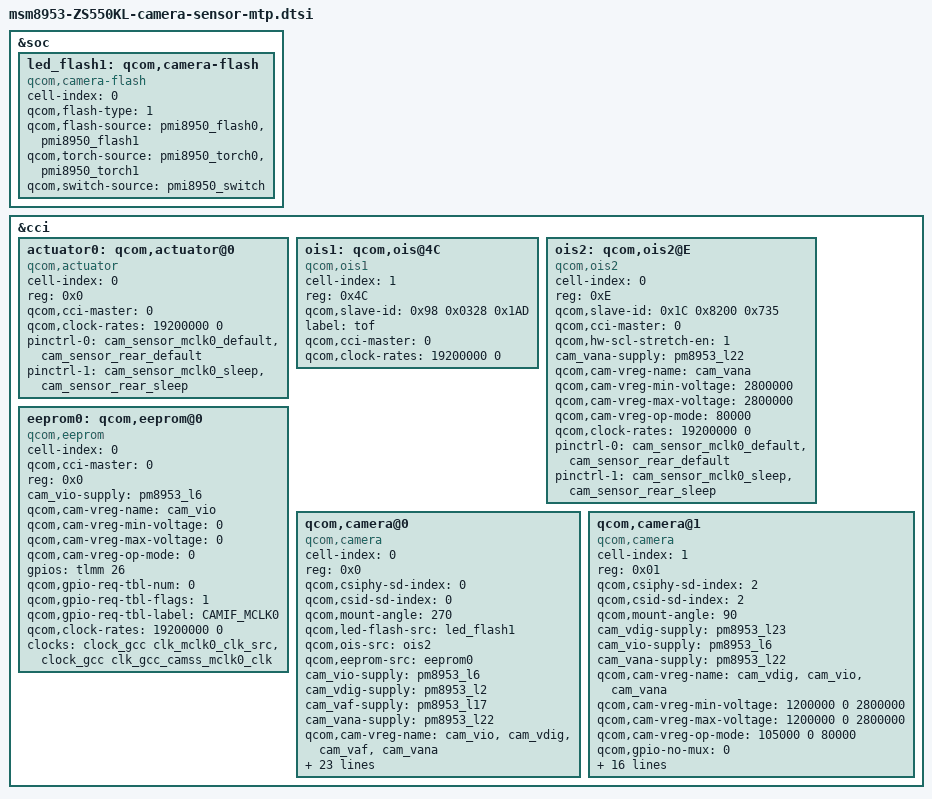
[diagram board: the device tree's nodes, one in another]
/*
 * Copyright (c) 2015-2016, The Linux Foundation. All rights reserved.
 *
 * This program is free software; you can redistribute it and/or modify
 * it under the terms of the GNU General Public License version 2 and
 * only version 2 as published by the Free Software Foundation.
 *
 * This program is distributed in the hope that it will be useful,
 * but WITHOUT ANY WARRANTY; without even the implied warranty of
 * MERCHANTABILITY or FITNESS FOR A PARTICULAR PURPOSE.  See the
 * GNU General Public License for more details.
 */

&soc {

	led_flash1: qcom,camera-flash {
		cell-index = <0>;
		compatible = "qcom,camera-flash";
		qcom,flash-type = <1>;
		qcom,flash-source = <&pmi8950_flash0 &pmi8950_flash1>;
		qcom,torch-source = <&pmi8950_torch0 &pmi8950_torch1>;
		qcom,switch-source = <&pmi8950_switch>;
	};
	
};

&cci {
/*
	led_flash0: qcom,camera-flash@37 {
		cell-index = <0>;
		reg = <0x37>;
		qcom,slave-id = <0x6E 0x00 0x0011>;
		compatible = "qcom,camera-flash";
		label = "sky81296";
		qcom,flash-type = <1>;
		qcom,enable_pinctrl;
		pinctrl-names = "cam_flash_default", "cam_flash_suspend";
		pinctrl-0 = <&rear_flash_led_enable>;
		pinctrl-1 = <&rear_flash_led_disable>;
		gpios = <&tlmm 25 0>;
		qcom,gpio-flash-en = <0>;
		qcom,gpio-req-tbl-num = <0>;
		qcom,gpio-req-tbl-flags = <0>;
		qcom,gpio-req-tbl-label = "FLASH_EN";
		qcom,cci-master = <0>;
	};
	*/
	actuator0: qcom,actuator@0 {
		cell-index = <0>;
		reg = <0x0>;
		compatible = "qcom,actuator";
		qcom,cci-master = <0>;
		qcom,clock-rates = <19200000 0>;

		pinctrl-names = "cam_default", "cam_suspend";
		pinctrl-0 = <&cam_sensor_mclk0_default
				&cam_sensor_rear_default>;
		pinctrl-1 = <&cam_sensor_mclk0_sleep &cam_sensor_rear_sleep>;
	};
	/*
	actuator1: qcom,actuator@1 {
		cell-index = <1>;
		reg = <0x18>;
		compatible = "qcom,actuator";
		qcom,cci-master = <0>;
		cam_vaf-supply = <&pm8953_l17>;
		qcom,cam-vreg-name = "cam_vaf";
		qcom,cam-vreg-min-voltage = <2850000>;
		qcom,cam-vreg-max-voltage = <2850000>;
		qcom,cam-vreg-op-mode = <100000>;
		qcom,clock-rates = <19200000 0>;

		pinctrl-names = "cam_default", "cam_suspend";
		pinctrl-0 = <&cam_sensor_mclk1_default
			&cam_sensor_front1_default>;
		pinctrl-1 = <&cam_sensor_mclk1_sleep &cam_sensor_front1_sleep>;
	};	
	*/
	ois1: qcom,ois@4C {
                cell-index = <1>;
                reg = <0x4C>;
                qcom,slave-id = <0x98 0x0328 0x1AD>;
                compatible = "qcom,ois1";
                label = "tof";
                qcom,cci-master = <0>;                
                qcom,clock-rates = <19200000 0>;
        };

	ois2: qcom,ois2@E {
		cell-index = <0>;
		reg = <0xE>;
		qcom,slave-id = <0x1C 0x8200 0x735>;
		compatible = "qcom,ois2";
		qcom,cci-master = <0>;
		qcom,hw-scl-stretch-en = <1>;
		cam_vana-supply = <&pm8953_l22>;
		qcom,cam-vreg-name = "cam_vana";
		qcom,cam-vreg-min-voltage = <2800000>;
		qcom,cam-vreg-max-voltage = <2800000>;
		qcom,cam-vreg-op-mode = <80000>;
		
		qcom,clock-rates = <19200000 0>;

		pinctrl-names = "cam_default", "cam_suspend";
		pinctrl-0 = <&cam_sensor_mclk0_default
				&cam_sensor_rear_default>;
		pinctrl-1 = <&cam_sensor_mclk0_sleep &cam_sensor_rear_sleep>;
	
	};
	
	eeprom0: qcom,eeprom@0 {
		cell-index = <0>;
		compatible = "qcom,eeprom";
		qcom,cci-master = <0>;
		reg = <0x0>;
		//qcom,eeprom-name = "imx298_gt24c16";
		//qcom,slave-addr = "0xA8";
		cam_vio-supply = <&pm8953_l6>;
		qcom,cam-vreg-name = "cam_vio";
		qcom,cam-vreg-min-voltage = <0>;
		qcom,cam-vreg-max-voltage = <0>;
		qcom,cam-vreg-op-mode = <0>;		
		gpios = <&tlmm 26 0>;
		qcom,gpio-req-tbl-num = <0>;
		qcom,gpio-req-tbl-flags = <1>;
		qcom,gpio-req-tbl-label = "CAMIF_MCLK0";
		//qcom,mclk-19200000;
		status = "ok";
		qcom,clock-rates = <19200000 0>;

		clocks = <&clock_gcc clk_mclk0_clk_src>,
				<&clock_gcc clk_gcc_camss_mclk0_clk>;
		clock-names = "cam_src_clk", "cam_clk";
	};
	
/*
	eeprom1: qcom,eeprom@1 {
		cell-index = <1>;
		compatible = "qcom,eeprom";
		qcom,cci-master = <0>;
		reg = <0x01>;
		qcom,eeprom-name = "imx298f_gt24c16";
		qcom,slave-addr = "0xA8";
		qcom,i2c-freq-mode = <2>;

		cam_vdig-supply = <&pm8953_l23>;
		cam_vio-supply = <&pm8953_l6>;
		cam_vana-supply = <&pm8953_l22>;
		cam_vaf-supply = <&pm8953_l17>;
		qcom,cam-vreg-name = "cam_vdig", "cam_vio", "cam_vana",
					"cam_vaf";
		qcom,cam-vreg-min-voltage = <1100000 0 2800000 2850000>;
		qcom,cam-vreg-max-voltage = <1100000 0 2800000 2850000>;
		qcom,cam-vreg-op-mode = <105000 0 80000 100000>;
		qcom,gpio-no-mux = <0>;
		pinctrl-names = "cam_default", "cam_suspend";
		pinctrl-0 = <&cam_sensor_mclk1_default
				&cam_sensor_front1_default
				&cam_sensor_vana>;
		pinctrl-1 = <&cam_sensor_mclk1_sleep
				&cam_sensor_front1_sleep
				&cam_sensor_vana_sleep>;
		gpios = <&tlmm 27 0>,
			<&tlmm 130 0>,
			<&tlmm 46 0>;
		qcom,gpio-standby = <1>;
		qcom,gpio-vana = <2>;
		qcom,gpio-req-tbl-num = <0 1 2>;
		qcom,gpio-req-tbl-flags = <1 0 0>;
		qcom,gpio-req-tbl-label = "CAMIF_MCLK2",
					  "CAM_STANDBY2",
					  "CAM_VANA";
		//qcom,mclk-19200000;
		status = "ok";
		qcom,clock-rates = <19200000 0>;

		clocks = <&clock_gcc clk_mclk1_clk_src>,
			<&clock_gcc clk_gcc_camss_mclk1_clk>;
		clock-names = "cam_src_clk", "cam_clk";
	};
*/
	/*
	eeprom1: qcom,eeprom@1 {
		cell-index = <1>;
		reg = <0x1>;
		qcom,eeprom-name = "sunny_8865";
		compatible = "qcom,eeprom";
		qcom,slave-addr = <0x6c>;
		qcom,cci-master = <0>;
		qcom,num-blocks = <8>;

		qcom,page0 = <1 0x0100 2 0x01 1 1>;
		qcom,poll0 = <0 0x0 2 0x0 1 0>;
		qcom,mem0 = <0 0x0 2 0x0 1 0>;

		qcom,page1 = <1 0x5002 2 0x00 1 0>;
		qcom,poll1 = <0 0x0 2 0x0 1 0>;
		qcom,mem1 = <0 0x0 2 0x0 1 0>;

		qcom,page2 = <1 0x3d84 2 0xc0 1 0>;
		qcom,poll2 = <0 0x0 2 0x0 1 0>;
		qcom,mem2 = <0 0x0 2 0x0 1 0>;

		qcom,page3 = <1 0x3d88 2 0x70 1 0>;
		qcom,poll3 = <0 0x0 2 0x0 1 0>;
		qcom,mem3 = <0 0x0 2 0x0 1 0>;

		qcom,page4 = <1 0x3d89 2 0x10 1 0>;
		qcom,poll4 = <0 0x0 2 0x0 1 0>;
		qcom,mem4 = <0 0x0 2 0x0 1 0>;

		qcom,page5 = <1 0x3d8a 2 0x70 1 0>;
		qcom,poll5 = <0 0x0 2 0x0 1 0>;
		qcom,mem5 = <0 0x0 2 0x0 1 0>;

		qcom,page6 = <1 0x3d8b 2 0xf4 1 0>;
		qcom,poll6 = <0 0x0 2 0x0 1 0>;
		qcom,mem6 = <0 0x0 2 0x0 1 0>;

		qcom,page7 = <1 0x3d81 2 0x01 1 10>;
		qcom,poll7 = <0 0x0 2 0x0 1 1>;
		qcom,mem7 = <1536 0x7010 2 0 1 0>;

		cam_vdig-supply = <&pm8953_l23>;
		cam_vana-supply = <&pm8953_l22>;
		cam_vio-supply = <&pm8953_l6>;
		cam_vaf-supply = <&pm8953_l17>;
		qcom,cam-vreg-name = "cam_vdig", "cam_vio", "cam_vana",
			"cam_vaf";
		qcom,cam-vreg-min-voltage = <1200000 0 2800000 2850000>;
		qcom,cam-vreg-max-voltage = <1200000 0 2800000 2850000>;
		qcom,cam-vreg-op-mode = <105000 0 80000 100000>;
		qcom,gpio-no-mux = <0>;
		pinctrl-names = "cam_default", "cam_suspend";
		pinctrl-0 = <&cam_sensor_mclk1_default
			&cam_sensor_front1_default>;
		pinctrl-1 = <&cam_sensor_mclk1_sleep &cam_sensor_front1_sleep>;
		gpios = <&tlmm 27 0>,
			<&tlmm 129 0>,
			<&tlmm 130 0>;
		qcom,gpio-reset = <1>;
		qcom,gpio-standby = <2>;
		qcom,gpio-req-tbl-num = <0 1 2>;
		qcom,gpio-req-tbl-flags = <1 0 0>;
		qcom,gpio-req-tbl-label = "CAMIF_MCLK2",
					  "CAM_RESET2",
					  "CAM_STANDBY2";
		qcom,cam-power-seq-type = "sensor_vreg", "sensor_vreg",
			"sensor_vreg",
			"sensor_gpio", "sensor_gpio" , "sensor_clk";
		qcom,cam-power-seq-val = "cam_vdig", "cam_vana", "cam_vio",
			"sensor_gpio_reset", "sensor_gpio_standby",
			"sensor_cam_mclk";
		qcom,cam-power-seq-cfg-val = <1 1 1 1 1 24000000>;
		qcom,cam-power-seq-delay = <1 1 1 30 30 5>;
		status = "ok";
		clocks = <&clock_gcc clk_mclk1_clk_src>,
			<&clock_gcc clk_gcc_camss_mclk1_clk>;
		clock-names = "cam_src_clk", "cam_clk";
	};
	*/
	qcom,camera@0 {
		cell-index = <0>;
		compatible = "qcom,camera";
		reg = <0x0>;
		qcom,csiphy-sd-index = <0>;
		qcom,csid-sd-index = <0>;
		qcom,mount-angle = <270>;
		qcom,led-flash-src = <&led_flash1>;
		qcom,ois-src=<&ois2>;
		qcom,eeprom-src = <&eeprom0>;
		//qcom,actuator-src = <&actuator0>;
		cam_vio-supply = <&pm8953_l6>;
		cam_vdig-supply = <&pm8953_l2>;
		cam_vaf-supply = <&pm8953_l17>;
		cam_vana-supply = <&pm8953_l22>;
		qcom,cam-vreg-name = "cam_vio", "cam_vdig", "cam_vaf", "cam_vana";
		qcom,cam-vreg-min-voltage = <0 1100000 2850000 2800000>;
		qcom,cam-vreg-max-voltage = <0 1100000 2850000 2800000>;
		qcom,cam-vreg-op-mode = <0 105000 100000 80000>;
		pinctrl-names = "cam_default", "cam_suspend";
		pinctrl-0 = <&cam_sensor_mclk0_default
				&cam_sensor_rear_default  &cam_sensor_rear_vcm_en_default>;//cam_sensor_rear_flash_en_default
		pinctrl-1 = <&cam_sensor_mclk0_sleep 
		                  &cam_sensor_rear_sleep  &cam_sensor_rear_vcm_en_sleep>;  //cam_sensor_rear_flash_en_sleep
		gpios = <&tlmm 26 0>,
			<&tlmm 39 0>;
		qcom,gpio-standby = <1>;
		qcom,gpio-req-tbl-num = <0 1>;
		qcom,gpio-req-tbl-flags = <1 0>;
		qcom,gpio-req-tbl-label = "CAMIF_MCLK0",
			"CAM_STANDBY0";
		qcom,sensor-position = <0>;
		qcom,sensor-mode = <0>;
		qcom,cci-master = <0>;
		//qcom,mclk-19200000;
		status = "ok";
		clocks = <&clock_gcc clk_mclk0_clk_src>,
				<&clock_gcc clk_gcc_camss_mclk0_clk>;
		clock-names = "cam_src_clk", "cam_clk";
		qcom,clock-rates = <19200000 0>;
	};
	qcom,camera@1 {
		cell-index = <1>;
		compatible = "qcom,camera";
		reg = <0x01>;
		qcom,csiphy-sd-index = <2>;
		qcom,csid-sd-index = <2>;
		qcom,mount-angle = <90>;
		//qcom,led-flash-src = <&led_flash1>;
		//qcom,eeprom-src = <&eeprom1>;
		//qcom,actuator-src = <&actuator1>;
		cam_vdig-supply = <&pm8953_l23>;
		cam_vio-supply = <&pm8953_l6>;
		cam_vana-supply = <&pm8953_l22>;
		//cam_vaf-supply = <&pm8953_l17>;
		qcom,cam-vreg-name = "cam_vdig", "cam_vio", "cam_vana";
					//"cam_vaf";
		//qcom,cam-vreg-min-voltage = <1100000 0 2800000 2850000>;
		//qcom,cam-vreg-max-voltage = <1100000 0 2800000 2850000>;
		//qcom,cam-vreg-op-mode = <105000 0 80000 100000>;
		qcom,cam-vreg-min-voltage = <1200000 0 2800000>;
		qcom,cam-vreg-max-voltage = <1200000 0 2800000>;
		qcom,cam-vreg-op-mode = <105000 0 80000>;
		qcom,gpio-no-mux = <0>;
		pinctrl-names = "cam_default", "cam_suspend";
		pinctrl-0 = <&cam_sensor_mclk1_default
				&cam_sensor_front1_default>;
		pinctrl-1 = <&cam_sensor_mclk1_sleep
				&cam_sensor_front1_sleep>;
		gpios = <&tlmm 27 0>,
			<&tlmm 130 0>;
		qcom,gpio-reset = <1>;
		qcom,gpio-req-tbl-num = <0 1>;
		qcom,gpio-req-tbl-flags = <1 0>;
		qcom,gpio-req-tbl-label = "CAMIF_MCLK2",
					  "CAM_RESET2";
		qcom,sensor-position = <1>;
		qcom,sensor-mode = <1>;
		qcom,cci-master = <0>;
		//qcom,mclk-19200000;
		status = "ok";
		clocks = <&clock_gcc clk_mclk1_clk_src>,
			<&clock_gcc clk_gcc_camss_mclk1_clk>;
		clock-names = "cam_src_clk", "cam_clk";
		qcom,clock-rates = <19200000 0>;
	};
};
